# MKW21Z4 register map
Vendor: Freescale Semiconductor, Inc.; Series: Kinetis_W; File version: 1.6
CPU: CM0PLUS r0p0, little endian, no MPU, no FPU, VTOR, 2 interrupt priority bits
Registers are 16-bit, read-write, no defined reset value unless marked. A register's access mark holds for its fields unless they carry their own. Offsets are from the block's base; [hi:lo] are bit positions; {n}, {i} and the like mark numbered series; 'fields as' and 'values as' point back to an identical list.

## TSI0 — Touch sense input
Base 0x40045000; register names take the prefix TSI0_
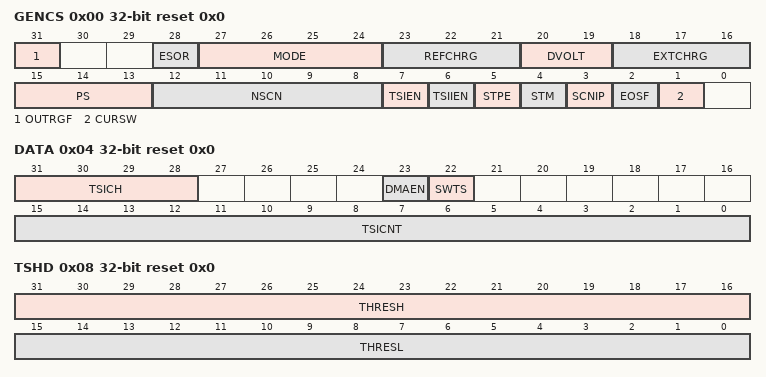
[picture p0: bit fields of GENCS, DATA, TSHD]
0x00 GENCS 32-bit reset 0x0 — TSI General Control and Status Register
  [31] OUTRGF — Out of Range Flag.
  [28] ESOR — End-of-scan or Out-of-Range Interrupt Selection
    0=Out-of-range interrupt is allowed; 1=End-of-scan interrupt is allowed
  [27:24] MODE — TSI analog modes setup and status bits.
    0=Set TSI in capacitive sensing(non-noise detection) mode; 4=Set TSI analog to work in single threshold noise detection mode and the frequency limitation circuit is disabled; 8=Set TSI analog to work in single threshold noise detection mode and the frequency limitation circuit is enabled to work in higher frequencies operations; 12=Set TSI analog to work in automatic noise detection mode
  [23:21] REFCHRG
    0=500 nA; 1=1 uA; 2=2 uA; 3=4 uA; 4=8 uA; 5=16 uA; 6=32 uA; 7=64 uA
  [20:19] DVOLT
    0=DV = 1.026 V; VP = 1.328 V; Vm = 0.302 V; 1=DV = 0.592 V; VP = 1.111 V; Vm = 0.519 V; 2=DV = 0.342 V; VP = 0.986 V; Vm = 0.644 V; 3=DV = 0.197 V; VP = 0.914 V; Vm = 0.716 V
  [18:16] EXTCHRG
    values as REFCHRG
  [15:13] PS
    0=Electrode Oscillator Frequency divided by 1; 1=Electrode Oscillator Frequency divided by 2; 2=Electrode Oscillator Frequency divided by 4; 3=Electrode Oscillator Frequency divided by 8; 4=Electrode Oscillator Frequency divided by 16; 5=Electrode Oscillator Frequency divided by 32; 6=Electrode Oscillator Frequency divided by 64; 7=Electrode Oscillator Frequency divided by 128
  [12:8] NSCN
    0=Once per electrode; 1=Twice per electrode; {v}={v+1} times per electrode (v=2..31)
  [7] TSIEN — Touch Sensing Input Module Enable
    0=TSI module disabled; 1=TSI module enabled
  [6] TSIIEN — Touch Sensing Input Interrupt Enable
    0=TSI interrupt is disabled; 1=TSI interrupt is enabled
  [5] STPE — TSI STOP Enable
    0=TSI is disabled when MCU goes into low power mode; 1=Allows TSI to continue running in all low power modes
  [4] STM — Scan Trigger Mode
    0=Software trigger scan; 1=Hardware trigger scan
  [3] SCNIP ro — Scan In Progress Status
    0=No scan in progress; 1=Scan in progress
  [2] EOSF — End of Scan Flag
    0=Scan not complete; 1=Scan complete
  [1] CURSW
    0=The current source pair are not swapped; 1=The current source pair are swapped
0x04 DATA 32-bit reset 0x0 — TSI DATA Register
  [31:28] TSICH
    {v}=Channel {v} (v=0..15)
  [23] DMAEN — DMA Transfer Enabled
    0=Interrupt is selected when the interrupt enable bit is set and the corresponding TSI events assert; 1=DMA transfer request is selected when the interrupt enable bit is set and the corresponding TSI events assert
  [22] SWTS wo — Software Trigger Start
    0=No effect; 1=Start a scan to determine which channel is specified by TSI_DATA[TSICH]
  [15:0] TSICNT ro — TSI Conversion Counter Value
0x08 TSHD 32-bit reset 0x0 — TSI Threshold Register
  [31:16] THRESH — TSI Wakeup Channel High-threshold
  [15:0] THRESL — TSI Wakeup Channel Low-threshold

## XCVR_PHY_REGS — XCVR_PHY
Base 0x4005C400
0x00 PHY_PRE_REF0 32-bit reset 0xFDDDEB39 — PREAMBLE REFERENCE WAVEFORM 0
  [31:0] FSK_PREAMBLE_REF0 — Base preamble reference waveform containing sixteen 5-bit phase values
0x04 PRE_REF1 32-bit reset 0xBEFBFFFF — PREAMBLE REFERENCE WAVEFORM 1
  [31:0] FSK_PREAMBLE_REF1 — Base preamble reference waveform containing sixteen 5-bit phase values
0x08 PRE_REF2 32-bit reset 0xCE75 — PREAMBLE REFERENCE WAVEFORM 2
  [15:0] FSK_PREAMBLE_REF2 — Base preamble reference waveform containing sixteen 5-bit phase values
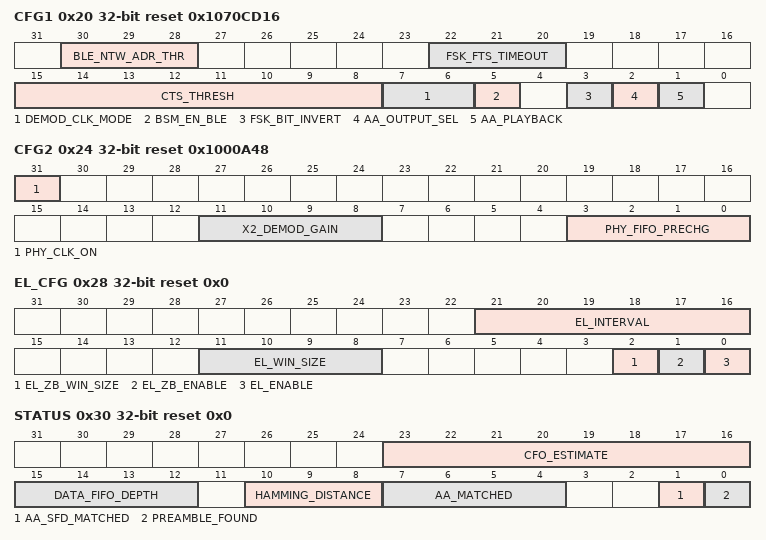
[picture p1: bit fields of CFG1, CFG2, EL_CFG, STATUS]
0x20 CFG1 32-bit reset 0x1070CD16 — PHY CONFIGURATION REGISTER 1
  [30:28] BLE_NTW_ADR_THR — BLE Network Address Match Bit Error Threshold
  [22:20] FSK_FTS_TIMEOUT
    {v}={v+4} symbols (v=0..7)
  [15:8] CTS_THRESH — CTS (Coarse Timing Search) Correlation Threshold
  [7:6] DEMOD_CLK_MODE — Demodulator Clock Mode
    0=Normal; 1=Demodulate all samples
  [5] BSM_EN_BLE — BLE Bit Streaming Mode Enable bit
    0=BSM for BLE disabled; 1=BSM for BLE enabled
  [3] FSK_BIT_INVERT
  [2] AA_OUTPUT_SEL — Access Address Output Select
    0=demodulated; 1=matched
  [1] AA_PLAYBACK — Access Address Playback
0x24 CFG2 32-bit reset 0x1000A48 — PHY CONFIGURATION REGISTER 2
  [31] PHY_CLK_ON — Force PHY Clock On (testmode)
    0=PHY clock is enabled by TSM output: rx_phy_en; 1=PHY clock is forced on at all times
  [11:8] X2_DEMOD_GAIN
  [3:0] PHY_FIFO_PRECHG — PHY FIFO Precharge Level
0x28 EL_CFG 32-bit reset 0x0 — PHY EARLY/LATE CONFIGURATION REGISTER
  [21:16] EL_INTERVAL
  [11:8] EL_WIN_SIZE
  [2] EL_ZB_WIN_SIZE
    0=2 symbols; 1=3 symbols
  [1] EL_ZB_ENABLE
    0=Disable Early/Late; 1=Enable Early/Late
  [0] EL_ENABLE
    0=Disable Early/Late; 1=Enable Early/Late
0x2C NTW_ADR_BSM 32-bit reset 0x0 — PHY NETWORK ADDRESS FOR BSM
0x30 STATUS 32-bit ro reset 0x0 — PHY STATUS REGISTER
  [23:16] CFO_ESTIMATE — Carrier Frequency Offset Estimate
  [15:12] DATA_FIFO_DEPTH
  [10:8] HAMMING_DISTANCE
  [7:4] AA_MATCHED — Access Address Matched
    0=No Network Address has matched; 1=Network Address 0 has matched; 2=Network Address 1 has matched; 4=Network Address 2 has matched; 8=Network Address 3 has matched
  [1] AA_SFD_MATCHED — Access Address or SFD Found
  [0] PREAMBLE_FOUND
